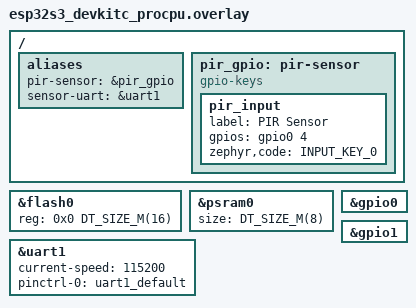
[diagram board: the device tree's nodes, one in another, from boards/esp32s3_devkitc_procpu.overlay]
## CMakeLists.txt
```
# SPDX-License-Identifier: Apache-2.0
# ESP32-S3 Edge AI Gateway - Phase 1 Build Configuration

cmake_minimum_required(VERSION 3.20.0)

find_package(Zephyr REQUIRED HINTS $ENV{ZEPHYR_BASE})

project(esp32s3_edge_ai_gateway)

# 头文件路径
target_include_directories(app PRIVATE include)

# 源文件
target_sources(app PRIVATE
	src/main.c
	src/drivers/pir.c
	src/drivers/uart_driver.c
	src/drivers/lighting.c
	src/logic/presence_state.c
	src/logic/time_period.c
	src/logic/rule_engine.c
	src/logic/fade_control.c
)
```

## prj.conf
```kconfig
# ESP32-S3 Edge AI Gateway Project Configuration
# Phase 1: 基础硬件通信模块

# ================================================================
# GPIO Support
# ================================================================
CONFIG_GPIO=y

# ================================================================
# Serial/UART Support (驱动板通信 + 调试控制台)
# ================================================================
CONFIG_SERIAL=y
CONFIG_UART_INTERRUPT_DRIVEN=y
CONFIG_UART_ASYNC_API=y
CONFIG_UART_ESP32=y

# ================================================================
# PSRAM (N16R8模块 8MB Octal SPI)
# ================================================================
CONFIG_ESP_SPIRAM=y
# CONFIG_ESP_SPIRAM_SIZE is set via DTS in overlay

# ================================================================
# Logging
# ================================================================
CONFIG_LOG=y
CONFIG_LOG_DEFAULT_LEVEL=3
CONFIG_LOG_PRINTK=y

# ================================================================
# Console
# ================================================================
CONFIG_CONSOLE=y
CONFIG_UART_CONSOLE=y

# ================================================================
# 内核配置
# ================================================================
CONFIG_MAIN_THREAD_PRIORITY=10
CONFIG_SYSTEM_WORKQUEUE_STACK_SIZE=2048

# ================================================================
# Networking Support
# ================================================================
CONFIG_NETWORKING=y
CONFIG_NET_NATIVE=y

# ================================================================
# WiFi Support (Phase 2: WF-001)
# ================================================================
CONFIG_WIFI=y
CONFIG_WIFI_ESP32=y
CONFIG_NET_L2_ETHERNET=y
CONFIG_NET_IPV4=y
CONFIG_NET_UDP=y
CONFIG_NET_DHCPV4=y
CONFIG_NET_SOCKETS=y
CONFIG_NET_SOCKETS_POLL_MAX=4

# ================================================================
# Network Buffer Configuration
# ================================================================
CONFIG_NET_PKT_RX_COUNT=16
CONFIG_NET_PKT_TX_COUNT=16
CONFIG_NET_BUF_RX_COUNT=32
CONFIG_NET_BUF_TX_COUNT=32
CONFIG_NET_BUF_DATA_SIZE=128

# ================================================================
# DNS Client (WF-012)
# ================================================================
CONFIG_DNS_RESOLVER=y
CONFIG_DNS_SERVER_IP_ADDRESSES=y

# ================================================================
# SNTP Time Sync (WF-006 ~ WF-010)
# ================================================================
CONFIG_SNTP=y

# ================================================================
# HTTP Client (WF-011 ~ WF-015)
# ================================================================
CONFIG_HTTP_CLIENT=y

# ================================================================
# JSON Parser (WF-022)
# ================================================================
CONFIG_JSON_LIBRARY=y

# ================================================================
# Thread Stack Size (WiFi thread needs more)
# ================================================================
CONFIG_MAIN_STACK_SIZE=4096
CONFIG_SYSTEM_WORKQUEUE_STACK_SIZE=4096
```

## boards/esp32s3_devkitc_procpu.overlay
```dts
/*
 * ESP32-S3 DevKitC Board Overlay (N16R8)
 * Edge AI Gateway Project
 * 
 * Hardware Configuration:
 * - Flash: 16MB (修正N8→N16)
 * - PSRAM: 8MB Octal SPI
 * - GPIO4: PIR传感器输入 (内部上拉)
 * - UART1: 驱动板通信 (TX=GPIO17, RX=GPIO18, 115200bps 8N1)
 */

#include <zephyr/dt-bindings/input/input-event-codes.h>
#include <zephyr/dt-bindings/gpio/gpio.h>

/* ================================================================
 * Flash 修正: N16R8模块使用16MB Flash (默认DTS是8MB)
 * ================================================================ */
&flash0 {
	reg = <0x0 DT_SIZE_M(16)>;  /* 16MB */
};

/* ================================================================
 * PSRAM 启用: 8MB Octal SPI
 * psram0使用'size'属性而非'reg'(其父节点dcache0持有reg)
 * ================================================================ */
&psram0 {
	size = <DT_SIZE_M(8)>;  /* 8MB */
};

/* ================================================================
 * GPIO & 外设别名
 * ================================================================ */
/ {
	aliases {
		pir-sensor = &pir_gpio;
		sensor-uart = &uart1;
	};

	/* PIR传感器 GPIO4: 输入模式, 内部上拉 */
	pir_gpio: pir-sensor {
		compatible = "gpio-keys";
		pir_input: pir_input {
			label = "PIR Sensor";
			gpios = <&gpio0 4 (GPIO_ACTIVE_HIGH | GPIO_PULL_UP)>;
			zephyr,code = <INPUT_KEY_0>;
		};
	};
};

/* ================================================================
 * UART1: 驱动板通信 (GPIO17=TX, GPIO18=RX, 115200bps)
 * pinctrl在板级esp32s3_devkitc-pinctrl.dtsi中已定义
 * ================================================================ */
&uart1 {
	status = "okay";
	current-speed = <115200>;
	pinctrl-0 = <&uart1_default>;
	pinctrl-names = "default";
};

/* ================================================================
 * GPIO控制器启用
 * ================================================================ */
&gpio0 {
	status = "okay";
};

&gpio1 {
	status = "okay";
};
```

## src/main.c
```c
/*
 * ESP32-S3 Edge AI Gateway
 * Main Application Entry Point
 * Phase 3: AI推理系统模块
 *
 * 功能: PIR感应 + UART控制 + WiFi数据 + 环境感知 + AI推理 + 数据记录
 */

#include <zephyr/kernel.h>
#include <zephyr/logging/log.h>

/* Phase 1: 基础硬件通信 */
#include "pir.h"
#include "uart_driver.h"
#include "lighting.h"
#include "presence_state.h"
#include "time_period.h"
#include "rule_engine.h"
#include "fade_control.h"

/* Phase 2: WiFi数据服务 */
#include "wifi_manager.h"
#include "sntp_time_sync.h"
#include "http_client.h"
#include "weather_api.h"
#include "sunrise_sunset.h"
#include "env_dimming.h"

/* Phase 3: AI推理系统 */
#include "ai_infer.h"
#include "data_logger.h"

LOG_MODULE_REGISTER(main, CONFIG_LOG_DEFAULT_LEVEL);

/* ================================================================
 * WiFi状态回调
 * ================================================================ */
static void wifi_state_callback(wifi_state_t state)
{
	switch (state) {
	case WIFI_STATE_GOT_IP:
		LOG_INF("WiFi connected, starting data services...");
		/* 记录事件 */
		data_logger_log_lighting(EVENT_WEATHER_UPDATE, 0, 0, 0);
		break;
	case WIFI_STATE_DISCONNECTED:
		LOG_WRN("WiFi disconnected, using offline mode");
		break;
	default:
		break;
	}
}

/* ================================================================
 * 初始化流程
 * ================================================================ */
int main(void)
{
	int ret;

	LOG_INF("========================================");
	LOG_INF("ESP32-S3 Edge AI Gateway Starting...");
	LOG_INF("Phase 3: AI Inference System");
	LOG_INF("========================================");

	/* ============================================================
	 * Phase 1: 基础硬件初始化
	 * ============================================================ */

	ret = pir_init();
	if (ret < 0) { LOG_ERR("PIR init failed"); return ret; }

	ret = uart_driver_init();
	if (ret < 0) { LOG_ERR("UART init failed"); return ret; }

	ret = lighting_init();
	if (ret < 0) { LOG_ERR("Lighting init failed"); }

	ret = presence_state_init();
	if (ret < 0) { LOG_ERR("Presence FSM init failed"); }

	ret = rule_engine_init();
	if (ret < 0) { LOG_ERR("Rule engine init failed"); }

	ret = fade_control_init();
	if (ret < 0) { LOG_ERR("Fade control init failed"); }

	LOG_INF("Phase 1 complete!");

	/* ============================================================
	 * Phase 2: WiFi数据服务初始化
	 * ============================================================ */

	ret = wifi_manager_init();
	if (ret < 0) { LOG_ERR("WiFi manager init failed"); }
	wifi_manager_register_state_cb(wifi_state_callback);
	if (ret == 0) {
		wifi_manager_start();
	}

	ret = sntp_time_init();
	if (ret < 0) { LOG_ERR("SNTP init failed"); }
	if (ret == 0) {
		sntp_time_start();
	}

	ret = http_client_init();
	if (ret < 0) { LOG_ERR("HTTP client init failed"); }

	ret = weather_api_init();
	if (ret < 0) { LOG_ERR("Weather API init failed"); }
	if (ret == 0) {
		weather_api_start();
	}

	ret = sun_api_init();
	if (ret < 0) { LOG_ERR("Sunrise-sunset API init failed"); }
	if (ret == 0) {
		sun_api_start();
	}

	ret = env_dimming_init();
	if (ret < 0) { LOG_ERR("Environment dimming init failed"); }

	LOG_INF("Phase 2 complete!");

	/* ============================================================
	 * Phase 3: AI推理系统初始化
	 * ============================================================ */

	/* AI-021 ~ AI-022: 数据记录器初始化 */
	ret = data_logger_init();
	if (ret < 0) {
		LOG_ERR("Data logger init failed");
	}

	/* AI-008 ~ AI-010: AI推理引擎初始化 */
	ret = ai_infer_init();
	if (ret != AI_STATUS_OK) {
		LOG_WRN("AI inference init failed (err %d) - falling back to rules", ret);
		/* 继续运行, 使用规则引擎作为后备 */
	} else {
		LOG_INF("AI inference engine loaded!");

		/* AI-020: 启动AI推理线程 */
		ai_infer_thread_start();
	}

	LOG_INF("Phase 3 complete!");
	LOG_INF("System ready - entering main control loop");

	/* ================================================================
	 * 主控制循环
	 * ================================================================
	 * 周期: 每1秒执行一次
	 * 功能:
	 *   1. 更新人员状态机
	 *   2. 检查WiFi连接状态
	 *   3. AI推理或规则引擎计算
	 *   4. 渐变控制
	 *   5. 事件记录
	 */
	lighting_settings_t settings;
	lighting_settings_t prev_settings = {0, 0};
	env_dimming_result_t env_result;

	while (1) {
		/* 更新人员状态机 */
		presence_state_t presence = presence_state_update();

		/* 获取当前时段 */
		time_period_t period = time_period_get_current();

		/* 优先使用AI推理, 否则使用规则引擎 */
		if (ai_infer_is_ready()) {
			/* AI推理已在独立线程中运行, 这里只检查状态 */
			uint16_t cur_temp;
			uint8_t cur_bright;
			fade_get_current(&cur_temp, &cur_bright);

			settings.color_temp = cur_temp;
			settings.brightness = cur_bright;
		} else {
			/* 后备: 使用环境感知调光 (Phase 2) */
			ret = env_dimming_calculate(presence, period, &env_result);
			if (ret == 0) {
				settings = env_result.final_;
			} else {
				/* 最终后备: 基础规则引擎 */
				rule_calculate_settings(presence, period, &settings);
			}

			/* 执行渐变控制 */
			if (settings.color_temp != prev_settings.color_temp ||
			    settings.brightness != prev_settings.brightness) {

				LOG_INF("Rule: %s/%s → %dK @ %d%%",
					presence == PRESENCE_TIMEOUT ? "OFF" : "ON",
					time_period_name(period),
					settings.color_temp, settings.brightness);

				if (settings.brightness == 0) {
					fade_to_target(settings.color_temp, 0, 1000);
				} else {
					fade_to_target(settings.color_temp, settings.brightness, 2000);
				}

				/* 记录事件 */
				data_logger_log_lighting(
					settings.brightness == 0 ? EVENT_LIGHTS_OFF : EVENT_LIGHTS_ON,
					settings.color_temp, settings.brightness, 0);

				prev_settings = settings;
			}
		}

		/* WiFi离线处理 */
		if (!wifi_manager_is_connected()) {
			static bool offline_logged = false;
			if (!offline_logged) {
				LOG_WRN("WiFi offline - using defaults");
				offline_logged = true;
			}
		}

		/* 调试日志 */
		if (presence == PRESENCE_YES) {
			LOG_DBG("PRESENT | %s | %dK @ %d%%",
				time_period_name(period),
				settings.color_temp, settings.brightness);
		} else if (presence == PRESENCE_NO) {
			uint32_t sec = presence_get_absence_seconds();
			LOG_DBG("ABSENT %ds | %s", sec, time_period_name(period));
		}

		k_sleep(K_SECONDS(1));
	}

	return 0;
}
```

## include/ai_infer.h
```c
/*
 * AI Inference Engine - TFLM推理封装
 * Phase 3: AI-008 ~ AI-012, AI-017 ~ AI-020
 *
 * 功能: 模型加载、特征填充、推理执行、后处理
 */

#ifndef AI_INFER_H
#define AI_INFER_H

#include <stdint.h>
#include <stdbool.h>

/* ================================================================
 * AI-013: 特征结构定义
 * ================================================================ */
#define AI_FEATURE_COUNT  7

typedef struct {
	float hour_sin;           /* [-1, 1] 时间正弦编码 */
	float hour_cos;           /* [-1, 1] 时间余弦编码 */
	float sunset_proximity;   /* [-1, 1] 日落临近度 */
	float sunrise_hour_norm;  /* [0, 1] 日出时间归一化 */
	float sunset_hour_norm;   /* [0, 1] 日落时间归一化 */
	float weather;            /* [0, 1] 天气编码 */
	float presence;           /* {0, 1} 人员存在 */
} ai_features_t;

/* 输出结构 */
typedef struct {
	uint16_t color_temp;      /* 2700-6500 K */
	uint8_t brightness;       /* 0-100 % */
} ai_output_t;

/* 推理状态 */
typedef enum {
	AI_STATUS_OK = 0,
	AI_STATUS_ERROR_INIT = -1,
	AI_STATUS_ERROR_MODEL = -2,
	AI_STATUS_ERROR_TENSOR = -3,
	AI_STATUS_ERROR_INVOKE = -4,
	AI_STATUS_ERROR_INPUT = -5,
} ai_status_t;

/* ================================================================
 * AI-008 ~ AI-012: 初始化与推理
 * ================================================================ */

/**
 * @brief 初始化AI推理引擎 (AI-008 ~ AI-010)
 * @return AI_STATUS_OK=成功
 */
ai_status_t ai_infer_init(void);

/**
 * @brief 检查AI引擎是否就绪
 * @return true=已初始化
 */
bool ai_infer_is_ready(void);

/**
 * @brief 执行推理 (AI-017)
 * @param features 输入特征
 * @param output   输出结果
 * @return AI_STATUS_OK=成功
 */
ai_status_t ai_infer_run(const ai_features_t *features, ai_output_t *output);

/**
 * @brief 获取推理延迟 (AI-028)
 * @return 上次推理耗时(微秒)
 */
uint32_t ai_infer_get_latency_us(void);

/* ================================================================
 * AI-014 ~ AI-016: 特征工程
 * ================================================================ */

/**
 * @brief 计算时间特征 (AI-014)
 * @param hour 当前小时 (0-23)
 * @param features 输出特征结构
 */
void ai_calc_time_features(float hour, ai_features_t *features);

/**
 * @brief 计算日落临近度 (AI-015)
 * @param hour 当前小时
 * @param sunset_hour 日落时间(小时)
 * @return 临近度值 [-1, 1]
 */
float ai_calc_sunset_proximity(float hour, float sunset_hour);

/**
 * @brief 组装完整特征向量 (AI-016)
 * @param hour 当前小时
 * @param weather 天气编码 (0-1)
 * @param presence 人员存在 (0/1)
 * @param sunrise_hour 日出时间
 * @param sunset_hour 日落时间
 * @param features 输出特征结构
 */
void ai_assemble_features(float hour, float weather, float presence,
			  float sunrise_hour, float sunset_hour,
			  ai_features_t *features);

/* ================================================================
 * AI-018: 后处理
 * ================================================================ */

/**
 * @brief 推理结果后处理
 * - 无人强制关灯
 * - 深夜限制亮度
 * - 范围限制
 * @param raw_output 原始推理输出
 * @param presence   人员状态
 * @param hour       当前小时
 * @param final_output 最终输出
 */
void ai_post_process(const ai_output_t *raw_output, float presence,
		     float hour, ai_output_t *final_output);

/* ================================================================
 * AI-020: 推理线程
 * ================================================================ */

/**
 * @brief 启动AI推理线程
 */
void ai_infer_thread_start(void);

/**
 * @brief 停止AI推理线程
 */
void ai_infer_thread_stop(void);

/* 推理周期 */
#define AI_INFERENCE_INTERVAL_MS  30000  /* 30秒 */

/* ================================================================
 * P0: 非对称 Debounce 状态机参数
 * ================================================================ */

/* 上升沿延迟：0ms（开灯要快） */
#define PRESENCE_RISE_DELAY_MS      0

/* 下降沿延迟：5分钟（关灯要慢，用户可能只是静坐） */
#define PRESENCE_FALL_DELAY_MS      300000

/**
 * @brief 更新稳定 presence 状态
 * @param raw_presence 原始 PIR 状态 (0/1)
 * @param now_ms 当前时间戳 (毫秒)
 * @return 稳定的 presence 状态
 */
float ai_update_stable_presence(bool raw_presence, int64_t now_ms);

/**
 * @brief 获取当前稳定 presence 状态
 * @return 稳定状态 (0.0 或 1.0)
 */
float ai_get_stable_presence(void);

/**
 * @brief 重置 presence 状态机
 */
void ai_presence_reset(void);

#endif /* AI_INFER_H */
```

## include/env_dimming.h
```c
/*
 * Environment-Aware Dimming - 环境感知调光算法
 * Phase 2: WF-026 ~ WF-030
 *
 * 功能: 日落临近度计算、天气补偿、日落渐变、增强调光引擎
 */

#ifndef ENV_DIMMING_H
#define ENV_DIMMING_H

#include <stdint.h>
#include <stdbool.h>
#include "rule_engine.h"
#include "weather_api.h"
#include "sunrise_sunset.h"

/* 补偿参数 */
#define WEATHER_COMP_MAX       25    /* 天气补偿最大增加 25% */
#define SUNSET_PROX_MAX        15    /* 日落临近最大增加 15% */
#define SUNSET_PROX_RANGE_HR   2.0f  /* 日落临近范围: 前后2小时 */

/* 增强调光参数结构体 */
typedef struct {
	lighting_settings_t base;      /* 基础参数 (时段规则) */
	float weather_comp;           /* 天气补偿量 (%) */
	float sunset_comp;            /* 日落补偿量 (%) */
	lighting_settings_t final_;    /* 最终参数 */
} env_dimming_result_t;

/**
 * @brief 初始化环境感知调光模块 (WF-029)
 * @return 0=成功
 */
int env_dimming_init(void);

/**
 * @brief 计算日落临近度 (WF-026)
 * @return 0.0 ~ 1.0 (日落时刻为1.0)
 */
float env_calc_sunset_proximity(void);

/**
 * @brief 计算天气补偿量 (WF-027)
 * @param weather_code 天气编码 (0.0 ~ 1.0)
 * @return 补偿量 (%), 阴天增加最多
 */
float env_calc_weather_compensation(float weather_code);

/**
 * @brief 计算日落渐变补偿量 (WF-028)
 * @param proximity 日落临近度
 * @return 补偿量 (%)
 */
float env_calc_sunset_compensation(float proximity);

/**
 * @brief 增强调光引擎: 融合天气+日落补偿 (WF-029)
 * @param presence 人员状态
 * @param period   时段
 * @param result   输出结果
 * @return 0=成功
 */
int env_dimming_calculate(int presence, int period, env_dimming_result_t *result);

/**
 * @brief 获取增强后的照明参数 (便捷函数)
 * @param settings 输出照明参数
 * @return 0=成功
 */
int env_get_enhanced_settings(lighting_settings_t *settings);

/**
 * @brief 联调测试 (WF-030)
 * 打印各种场景下的调光参数
 */
void env_dimming_test(void);

#endif /* ENV_DIMMING_H */
```

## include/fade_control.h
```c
/*
 * Fade Control Module - 渐变控制
 * Phase 1: HW-020
 */

#ifndef FADE_CONTROL_H
#define FADE_CONTROL_H

#include <stdint.h>
#include <stdbool.h>
#include "lighting.h"

/* 默认渐变时间 */
#define FADE_DEFAULT_DURATION_MS  1000  /* 1秒 */
#define FADE_STEP_INTERVAL_MS     50    /* 每50ms更新一次 */

/**
 * @brief 初始化渐变控制模块
 * @return 0=成功
 */
int fade_control_init(void);

/**
 * @brief 平滑渐变到目标色温和光强
 * @param target_temp   目标色温 (2700-6500)
 * @param target_bright 目标光强 (0-100)
 * @param duration_ms   渐变时间 (毫秒)
 * @return 0=成功, 负值=失败
 */
int fade_to_target(uint16_t target_temp, uint8_t target_bright,
		   uint32_t duration_ms);

/**
 * @brief 立即设置 (无渐变)
 * @param temp   色温
 * @param bright 光强
 * @return 0=成功
 */
int fade_set_immediate(uint16_t temp, uint8_t bright);

/**
 * @brief 检查是否正在渐变中
 * @return true=正在渐变
 */
bool fade_is_in_progress(void);

/**
 * @brief 获取当前设置值
 * @param temp   输出当前色温
 * @param bright 输出当前光强
 */
void fade_get_current(uint16_t *temp, uint8_t *bright);

#endif /* FADE_CONTROL_H */
```

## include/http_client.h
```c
/*
 * HTTP Client - HTTP请求模块
 * Phase 2: WF-011 ~ WF-015
 *
 * 功能: HTTP GET请求、DNS解析、响应缓冲、超时处理
 */

#ifndef HTTP_CLIENT_H
#define HTTP_CLIENT_H

#include <stdint.h>
#include <stddef.h>

/* HTTP响应缓冲区大小 */
#define HTTP_RESPONSE_BUF_SIZE  4096

/* HTTP超时 */
#define HTTP_REQUEST_TIMEOUT_S  5

/* HTTP状态码 */
#define HTTP_STATUS_OK          200

/* HTTP响应结构体 */
typedef struct {
	int status_code;                   /* HTTP状态码 */
	char *body;                        /* 响应体 (动态分配或外部缓冲区) */
	size_t body_len;                   /* 响应体长度 */
	size_t buf_size;                   /* 缓冲区总大小 */
} http_response_t;

/**
 * @brief 初始化HTTP客户端 (WF-011)
 * @return 0=成功, 负值=失败
 */
int http_client_init(void);

/**
 * @brief 执行HTTP GET请求 (WF-013)
 * @param host     主机名 (如 "wttr.in")
 * @param path     路径 (如 "/Beijing?format=3")
 * @param port     端口 ("80" 或 "443")
 * @param response 输出响应结构体 (调用者分配body缓冲区)
 * @return 0=成功, 负值=失败
 */
int http_get(const char *host, const char *path, const char *port,
	     http_response_t *response);

/**
 * @brief 初始化HTTP响应结构体 (WF-014)
 * @param response 响应结构体
 * @param buf      外部提供的缓冲区 (至少HTTP_RESPONSE_BUF_SIZE)
 * @param buf_size 缓冲区大小
 */
void http_response_init(http_response_t *response, char *buf, size_t buf_size);

/**
 * @brief 清理HTTP响应
 * @param response 响应结构体
 */
void http_response_cleanup(http_response_t *response);

#endif /* HTTP_CLIENT_H */
```

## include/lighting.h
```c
/*
 * Lighting Command Interface - 驱动板调光控制
 * Phase 1: HW-013
 */

#ifndef LIGHTING_H
#define LIGHTING_H

#include <stdint.h>

/* 命令码定义 (驱动板协议) */
#define CMD_SET_COLOR_TEMP   0x01  /* 设置色温 (小端16位) */
#define CMD_SET_BRIGHTNESS   0x02  /* 设置光强 (1字节百分比) */
#define CMD_SET_BOTH         0x03  /* 同时设置色温+光强 */
#define CMD_GET_STATUS       0x04  /* 查询驱动板状态 */

/* 响应状态码 */
#define RESP_ACK             0x00  /* 成功确认 */
#define RESP_NAK             0xFF  /* 失败/拒绝 */

/* 参数范围 */
#define COLOR_TEMP_MIN       2700
#define COLOR_TEMP_MAX       6500
#define BRIGHTNESS_MIN       0
#define BRIGHTNESS_MAX       100

/**
 * @brief 初始化照明控制模块
 * @return 0=成功, 负值=失败
 */
int lighting_init(void);

/**
 * @brief 设置灯具色温
 * @param color_temp 色温值 (2700-6500K)
 * @return 0=成功, 负值=失败
 */
int lighting_set_color_temp(uint16_t color_temp);

/**
 * @brief 设置灯具光强
 * @param brightness 光强百分比 (0-100)
 * @return 0=成功, 负值=失败
 */
int lighting_set_brightness(uint8_t brightness);

/**
 * @brief 同时设置色温和光强
 * @param color_temp 色温值 (2700-6500K)
 * @param brightness 光强百分比 (0-100)
 * @return 0=成功, 负值=失败
 */
int lighting_set_both(uint16_t color_temp, uint8_t brightness);

/**
 * @brief 查询驱动板当前状态
 * @return 0=成功, 负值=失败
 */
int lighting_get_status(void);

#endif /* LIGHTING_H */
```

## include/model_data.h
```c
/*
 * Lighting MLP Model Data - INT8 Quantized
 * Auto-generated by train_model.py
 * DO NOT EDIT
 */

#ifndef LIGHTING_MODEL_DATA_H_
#define LIGHTING_MODEL_DATA_H_

#include <stdint.h>

const unsigned int g_lighting_model_data_len = 2648;
const alignas(16) unsigned char g_lighting_model_data[] = {
    0x20, 0x00, 0x00, 0x00, 0x54, 0x46, 0x4c, 0x33, 0x00, 0x00, 0x00, 0x00,
    0x14, 0x00, 0x20, 0x00, 0x1c, 0x00, 0x18, 0x00, 0x14, 0x00, 0x10, 0x00,
    0x0c, 0x00, 0x00, 0x00, 0x08, 0x00, 0x04, 0x00, 0x14, 0x00, 0x00, 0x00,
    0x1c, 0x00, 0x00, 0x00, 0x8c, 0x00, 0x00, 0x00, 0xe4, 0x00, 0x00, 0x00,
    0xbc, 0x02, 0x00, 0x00, 0xcc, 0x02, 0x00, 0x00, 0xe8, 0x09, 0x00, 0x00,
    0x03, 0x00, 0x00, 0x00, 0x01, 0x00, 0x00, 0x00, 0x04, 0x00, 0x00, 0x00,
    0xfa, 0xfc, 0xff, 0xff, 0x0c, 0x00, 0x00, 0x00, 0x1c, 0x00, 0x00, 0x00,
    0x3c, 0x00, 0x00, 0x00, 0x0f, 0x00, 0x00, 0x00, 0x73, 0x65, 0x72, 0x76,
    0x69, 0x6e, 0x67, 0x5f, 0x64, 0x65, 0x66, 0x61, 0x75, 0x6c, 0x74, 0x00,
    0x01, 0x00, 0x00, 0x00, 0x04, 0x00, 0x00, 0x00, 0x90, 0xff, 0xff, 0xff,
    0x07, 0x00, 0x00, 0x00, 0x04, 0x00, 0x00, 0x00, 0x08, 0x00, 0x00, 0x00,
    0x6f, 0x75, 0x74, 0x70, 0x75, 0x74, 0x5f, 0x30, 0x00, 0x00, 0x00, 0x00,
    0x01, 0x00, 0x00, 0x00, 0x04, 0x00, 0x00, 0x00, 0xce, 0xfd, 0xff, 0xff,
    0x04, 0x00, 0x00, 0x00, 0x0c, 0x00, 0x00, 0x00, 0x6b, 0x65, 0x72, 0x61,
    0x73, 0x5f, 0x74, 0x65, 0x6e, 0x73, 0x6f, 0x72, 0x00, 0x00, 0x00, 0x00,
    0x02, 0x00, 0x00, 0x00, 0x34, 0x00, 0x00, 0x00, 0x04, 0x00, 0x00, 0x00,
    0xdc, 0xff, 0xff, 0xff, 0x0a, 0x00, 0x00, 0x00, 0x04, 0x00, 0x00, 0x00,
    0x13, 0x00, 0x00, 0x00, 0x43, 0x4f, 0x4e, 0x56, 0x45, 0x52, 0x53, 0x49,
    0x4f, 0x4e, 0x5f, 0x4d, 0x45, 0x54, 0x41, 0x44, 0x41, 0x54, 0x41, 0x00,
    0x08, 0x00, 0x0c, 0x00, 0x08, 0x00, 0x04, 0x00, 0x08, 0x00, 0x00, 0x00,
    0x09, 0x00, 0x00, 0x00, 0x04, 0x00, 0x00, 0x00, 0x13, 0x00, 0x00, 0x00,
    0x6d, 0x69, 0x6e, 0x5f, 0x72, 0x75, 0x6e, 0x74, 0x69, 0x6d, 0x65, 0x5f,
    0x76, 0x65, 0x72, 0x73, 0x69, 0x6f, 0x6e, 0x00, 0x0b, 0x00, 0x00, 0x00,
    0xd4, 0x01, 0x00, 0x00, 0xcc, 0x01, 0x00, 0x00, 0xb4, 0x01, 0x00, 0x00,
    0x7c, 0x01, 0x00, 0x00, 0x2c, 0x01, 0x00, 0x00, 0xac, 0x00, 0x00, 0x00,
    0xa4, 0x00, 0x00, 0x00, 0x9c, 0x00, 0x00, 0x00, 0x94, 0x00, 0x00, 0x00,
    0x74, 0x00, 0x00, 0x00, 0x04, 0x00, 0x00, 0x00, 0x76, 0xfe, 0xff, 0xff,
    0x04, 0x00, 0x00, 0x00, 0x60, 0x00, 0x00, 0x00, 0x0c, 0x00, 0x00, 0x00,
    0x08, 0x00, 0x0e, 0x00, 0x08, 0x00, 0x04, 0x00, 0x08, 0x00, 0x00, 0x00,
    0x10, 0x00, 0x00, 0x00, 0x28, 0x00, 0x00, 0x00, 0x00, 0x00, 0x06, 0x00,
    0x08, 0x00, 0x04, 0x00, 0x06, 0x00, 0x00, 0x00, 0x04, 0x00, 0x00, 0x00,
    0x01, 0x00, 0x00, 0x00, 0xeb, 0x03, 0x00, 0x00, 0x0c, 0x00, 0x18, 0x00,
    0x14, 0x00, 0x10, 0x00, 0x0c, 0x00, 0x04, 0x00, 0x0c, 0x00, 0x00, 0x00,
    0x8a, 0x86, 0xd6, 0x43, 0x1b, 0x89, 0x45, 0x2d, 0x02, 0x00, 0x00, 0x00,
    0x02, 0x00, 0x00, 0x00, 0x04, 0x00, 0x00, 0x00, 0x06, 0x00, 0x00, 0x00,
    0x32, 0x2e, 0x32, 0x31, 0x2e, 0x30, 0x00, 0x00, 0xe2, 0xfe, 0xff, 0xff,
    0x04, 0x00, 0x00, 0x00, 0x10, 0x00, 0x00, 0x00, 0x31, 0x2e, 0x31, 0x34,
    0x2e, 0x30, 0x00, 0x00, 0x00, 0x00, 0x00, 0x00, 0x00, 0x00, 0x00, 0x00,
    0x2c, 0xfe, 0xff, 0xff, 0x30, 0xfe, 0xff, 0xff, 0x34, 0xfe, 0xff, 0xff,
    0x0a, 0xff, 0xff, 0xff, 0x04, 0x00, 0x00, 0x00, 0x70, 0x00, 0x00, 0x00,
    0xce, 0xc9, 0x1a, 0x24, 0x24, 0xfa, 0x81, 0x33, 0x7f, 0x3d, 0x59, 0x3c,
    0x06, 0xd0, 0xef, 0xe5, 0x1f, 0x0b, 0xfc, 0x2f, 0x7f, 0x81, 0xdb, 0x40,
    0xee, 0xb6, 0xc3, 0xe7, 0x1d, 0x50, 0x7f, 0x36, 0x16, 0x00, 0xc8, 0xed,
    0x8d, 0xc5, 0xaf, 0x81, 0xfb, 0xb5, 0xe5, 0xc3, 0x60, 0x04, 0xde, 0x20,
    0x7f, 0xfc, 0x9f, 0x81, 0xfe, 0x03, 0xf7, 0xcf, 0x7f, 0x13, 0xcf, 0x0c,
    0x26, 0xef, 0x20, 0x03, 0x00, 0x05, 0x39, 0x2c, 0x06, 0x81, 0x81, 0xd5,
    0x57, 0xc4, 0xca, 0x1a, 0x0c, 0xde, 0x66, 0x81, 0x8a, 0xb8, 0xc0, 0xc6,
    0x15, 0x44, 0x7f, 0xdb, 0xe0, 0x11, 0xf6, 0x29, 0x7a, 0x69, 0xf5, 0x3a,
    0x7f, 0x32, 0x2f, 0xe6, 0x2e, 0x00, 0x4d, 0xce, 0x81, 0xc6, 0x1b, 0xa8,
    0xf5, 0x7f, 0xcb, 0x1a, 0x86, 0xff, 0xff, 0xff, 0x04, 0x00, 0x00, 0x00,
    0x40, 0x00, 0x00, 0x00, 0x48, 0x17, 0x00, 0x00, 0x09, 0x2f, 0x00, 0x00,
    0x54, 0xfc, 0xff, 0xff, 0xd8, 0x08, 0x00, 0x00, 0x2c, 0x32, 0x00, 0x00,
    0x43, 0xfd, 0xff, 0xff, 0xdd, 0x01, 0x00, 0x00, 0xd3, 0x1e, 0x00, 0x00,
    0x11, 0xf6, 0xff, 0xff, 0x02, 0x21, 0x00, 0x00, 0xf3, 0x03, 0x00, 0x00,
    0x0d, 0xf3, 0xff, 0xff, 0x8b, 0xf3, 0xff, 0xff, 0xf3, 0x0c, 0x00, 0x00,
    0xbd, 0x22, 0x00, 0x00, 0x77, 0x0a, 0x00, 0x00, 0xd2, 0xff, 0xff, 0xff,
    0x04, 0x00, 0x00, 0x00, 0x20, 0x00, 0x00, 0x00, 0xb7, 0xdb, 0x24, 0xec,
    0xc5, 0x05, 0x1c, 0xbc, 0x3a, 0x81, 0xd5, 0x0b, 0x50, 0xdf, 0xe0, 0x22,
    0x9d, 0xe7, 0x2a, 0xaf, 0xed, 0x14, 0x4d, 0xd7, 0x31, 0x81, 0x23, 0x05,
    0x10, 0x07, 0xa2, 0xe4, 0x00, 0x00, 0x06, 0x00, 0x08, 0x00, 0x04, 0x00,
    0x06, 0x00, 0x00, 0x00, 0x04, 0x00, 0x00, 0x00, 0x08, 0x00, 0x00, 0x00,
    0x15, 0xfb, 0xff, 0xff, 0xed, 0xf7, 0xff, 0xff, 0x48, 0xff, 0xff, 0xff,
    0x4c, 0xff, 0xff, 0xff, 0x0f, 0x00, 0x00, 0x00, 0x4d, 0x4c, 0x49, 0x52,
    0x20, 0x43, 0x6f, 0x6e, 0x76, 0x65, 0x72, 0x74, 0x65, 0x64, 0x2e, 0x00,
    0x01, 0x00, 0x00, 0x00, 0x14, 0x00, 0x00, 0x00, 0x00, 0x00, 0x0e, 0x00,
    0x18, 0x00, 0x14, 0x00, 0x10, 0x00, 0x0c, 0x00, 0x08, 0x00, 0x04, 0x00,
    0x0e, 0x00, 0x00, 0x00, 0x14, 0x00, 0x00, 0x00, 0x1c, 0x00, 0x00, 0x00,
    0xe4, 0x00, 0x00, 0x00, 0xe8, 0x00, 0x00, 0x00, 0xec, 0x00, 0x00, 0x00,
    0x04, 0x00, 0x00, 0x00, 0x6d, 0x61, 0x69, 0x6e, 0x00, 0x00, 0x00, 0x00,
    0x03, 0x00, 0x00, 0x00, 0x8c, 0x00, 0x00, 0x00, 0x44, 0x00, 0x00, 0x00,
    0x10, 0x00, 0x00, 0x00, 0x00, 0x00, 0x0a, 0x00, 0x10, 0x00, 0x0c, 0x00,
    0x08, 0x00, 0x04, 0x00, 0x0a, 0x00, 0x00, 0x00, 0x0c, 0x00, 0x00, 0x00,
    0x10, 0x00, 0x00, 0x00, 0x01, 0x00, 0x00, 0x00, 0x01, 0x00, 0x00, 0x00,
    0x07, 0x00, 0x00, 0x00, 0x01, 0x00, 0x00, 0x00, 0x06, 0x00, 0x00, 0x00,
    0x00, 0x00, 0x0e, 0x00, 0x14, 0x00, 0x00, 0x00, 0x10, 0x00, 0x0c, 0x00,
    0x0b, 0x00, 0x04, 0x00, 0x0e, 0x00, 0x00, 0x00, 0x14, 0x00, 0x00, 0x00,
    0x00, 0x00, 0x00, 0x08, 0x10, 0x00, 0x00, 0x00, 0x14, 0x00, 0x00, 0x00,
    0x04, 0x00, 0x04, 0x00, 0x04, 0x00, 0x00, 0x00, 0x01, 0x00, 0x00, 0x00,
    0x06, 0x00, 0x00, 0x00, 0x03, 0x00, 0x00, 0x00, 0x05, 0x00, 0x00, 0x00,
    0x02, 0x00, 0x00, 0x00, 0x01, 0x00, 0x00, 0x00, 0x00, 0x00, 0x0e, 0x00,
    0x16, 0x00, 0x00, 0x00, 0x10, 0x00, 0x0c, 0x00, 0x0b, 0x00, 0x04, 0x00,
    0x0e, 0x00, 0x00, 0x00, 0x18, 0x00, 0x00, 0x00, 0x00, 0x00, 0x00, 0x08,
    0x18, 0x00, 0x00, 0x00, 0x1c, 0x00, 0x00, 0x00, 0x00, 0x00, 0x06, 0x00,
    0x08, 0x00, 0x07, 0x00, 0x06, 0x00, 0x00, 0x00, 0x00, 0x00, 0x00, 0x01,
    0x01, 0x00, 0x00, 0x00, 0x05, 0x00, 0x00, 0x00, 0x03, 0x00, 0x00, 0x00,
    0x00, 0x00, 0x00, 0x00, 0x04, 0x00, 0x00, 0x00, 0x03, 0x00, 0x00, 0x00,
    0x01, 0x00, 0x00, 0x00, 0x07, 0x00, 0x00, 0x00, 0x01, 0x00, 0x00, 0x00,
    0x00, 0x00, 0x00, 0x00, 0x08, 0x00, 0x00, 0x00, 0x7c, 0x05, 0x00, 0x00,
    0xec, 0x04, 0x00, 0x00, 0x58, 0x04, 0x00, 0x00, 0x14, 0x03, 0x00, 0x00,
    0xe8, 0x01, 0x00, 0x00, 0x24, 0x01, 0x00, 0x00, 0x80, 0x00, 0x00, 0x00,
    0x04, 0x00, 0x00, 0x00, 0xba, 0xfa, 0xff, 0xff, 0x00, 0x00, 0x00, 0x01,
    0x18, 0x00, 0x00, 0x00, 0x20, 0x00, 0x00, 0x00, 0x3c, 0x00, 0x00, 0x00,
    0x08, 0x00, 0x00, 0x00, 0x00, 0x00, 0x00, 0x09, 0x50, 0x00, 0x00, 0x00,
    0x02, 0x00, 0x00, 0x00, 0xff, 0xff, 0xff, 0xff, 0x02, 0x00, 0x00, 0x00,
    0xa4, 0xfa, 0xff, 0xff, 0x08, 0x00, 0x00, 0x00, 0x10, 0x00, 0x00, 0x00,
    0x01, 0x00, 0x00, 0x00, 0x80, 0xff, 0xff, 0xff, 0xff, 0xff, 0xff, 0xff,
    0x01, 0x00, 0x00, 0x00, 0x00, 0x00, 0x80, 0x3b, 0x1b, 0x00, 0x00, 0x00,
    0x53, 0x74, 0x61, 0x74, 0x65, 0x66, 0x75, 0x6c, 0x50, 0x61, 0x72, 0x74,
    0x69, 0x74, 0x69, 0x6f, 0x6e, 0x65, 0x64, 0x43, 0x61, 0x6c, 0x6c, 0x5f,
    0x31, 0x3a, 0x30, 0x00, 0x02, 0x00, 0x00, 0x00, 0x01, 0x00, 0x00, 0x00,
    0x02, 0x00, 0x00, 0x00, 0x32, 0xfb, 0xff, 0xff, 0x00, 0x00, 0x00, 0x01,
    0x18, 0x00, 0x00, 0x00, 0x20, 0x00, 0x00, 0x00, 0x40, 0x00, 0x00, 0x00,
    0x07, 0x00, 0x00, 0x00, 0x00, 0x00, 0x00, 0x09, 0x78, 0x00, 0x00, 0x00,
    0x02, 0x00, 0x00, 0x00, 0xff, 0xff, 0xff, 0xff, 0x02, 0x00, 0x00, 0x00,
    0x1c, 0xfb, 0xff, 0xff, 0x08, 0x00, 0x00, 0x00, 0x14, 0x00, 0x00, 0x00,
    0x01, 0x00, 0x00, 0x00, 0x4b, 0x00, 0x00, 0x00, 0x00, 0x00, 0x00, 0x00,
    0x00, 0x00, 0x00, 0x00, 0x01, 0x00, 0x00, 0x00, 0x58, 0xca, 0x33, 0x3d,
    0x3e, 0x00, 0x00, 0x00, 0x6c, 0x69, 0x67, 0x68, 0x74, 0x69, 0x6e, 0x67,
    0x5f, 0x6d, 0x6c, 0x70, 0x5f, 0x31, 0x2f, 0x6f, 0x75, 0x74, 0x70, 0x75,
    0x74, 0x5f, 0x31, 0x2f, 0x4d, 0x61, 0x74, 0x4d, 0x75, 0x6c, 0x3b, 0x6c,
    0x69, 0x67, 0x68, 0x74, 0x69, 0x6e, 0x67, 0x5f, 0x6d, 0x6c, 0x70, 0x5f,
    0x31, 0x2f, 0x6f, 0x75, 0x74, 0x70, 0x75, 0x74, 0x5f, 0x31, 0x2f, 0x42,
    0x69, 0x61, 0x73, 0x41, 0x64, 0x64, 0x00, 0x00, 0x02, 0x00, 0x00, 0x00,
    0x01, 0x00, 0x00, 0x00, 0x02, 0x00, 0x00, 0x00, 0xd2, 0xfb, 0xff, 0xff,
    0x00, 0x00, 0x00, 0x01, 0x18, 0x00, 0x00, 0x00, 0x20, 0x00, 0x00, 0x00,
    0x3c, 0x00, 0x00, 0x00, 0x06, 0x00, 0x00, 0x00, 0x00, 0x00, 0x00, 0x09,
    0x98, 0x00, 0x00, 0x00, 0x02, 0x00, 0x00, 0x00, 0xff, 0xff, 0xff, 0xff,
    0x10, 0x00, 0x00, 0x00, 0xbc, 0xfb, 0xff, 0xff, 0x08, 0x00, 0x00, 0x00,
    0x10, 0x00, 0x00, 0x00, 0x01, 0x00, 0x00, 0x00, 0x80, 0xff, 0xff, 0xff,
    0xff, 0xff, 0xff, 0xff, 0x01, 0x00, 0x00, 0x00, 0x79, 0x02, 0x08, 0x3c,
    0x61, 0x00, 0x00, 0x00, 0x6c, 0x69, 0x67, 0x68, 0x74, 0x69, 0x6e, 0x67,
    0x5f, 0x6d, 0x6c, 0x70, 0x5f, 0x31, 0x2f, 0x68, 0x69, 0x64, 0x64, 0x65,
    0x6e, 0x5f, 0x31, 0x5f, 0x31, 0x2f, 0x4d, 0x61, 0x74, 0x4d, 0x75, 0x6c,
    0x3b, 0x6c, 0x69, 0x67, 0x68, 0x74, 0x69, 0x6e, 0x67, 0x5f, 0x6d, 0x6c,
    0x70, 0x5f, 0x31, 0x2f, 0x68, 0x69, 0x64, 0x64, 0x65, 0x6e, 0x5f, 0x31,
    0x5f, 0x31, 0x2f, 0x52, 0x65, 0x6c, 0x75, 0x3b, 0x6c, 0x69, 0x67, 0x68,
    0x74, 0x69, 0x6e, 0x67, 0x5f, 0x6d, 0x6c, 0x70, 0x5f, 0x31, 0x2f, 0x68,
    0x69, 0x64, 0x64, 0x65, 0x6e, 0x5f, 0x31, 0x5f, 0x31, 0x2f, 0x42, 0x69,
    0x61, 0x73, 0x41, 0x64, 0x64, 0x00, 0x00, 0x00, 0x02, 0x00, 0x00, 0x00,
    0x01, 0x00, 0x00, 0x00, 0x10, 0x00, 0x00, 0x00, 0x1e, 0xfd, 0xff, 0xff,
    0x00, 0x00, 0x00, 0x01, 0x14, 0x00, 0x00, 0x00, 0xe8, 0x00, 0x00, 0x00,
    0x05, 0x00, 0x00, 0x00, 0x00, 0x00, 0x00, 0x09, 0x04, 0x01, 0x00, 0x00,
    0x6c, 0xfc, 0xff, 0xff, 0x08, 0x00, 0x00, 0x00, 0x8c, 0x00, 0x00, 0x00,
    0x10, 0x00, 0x00, 0x00, 0x00, 0x00, 0x00, 0x00, 0x00, 0x00, 0x00, 0x00,
    0x00, 0x00, 0x00, 0x00, 0x00, 0x00, 0x00, 0x00, 0x00, 0x00, 0x00, 0x00,
    0x00, 0x00, 0x00, 0x00, 0x00, 0x00, 0x00, 0x00, 0x00, 0x00, 0x00, 0x00,
    0x00, 0x00, 0x00, 0x00, 0x00, 0x00, 0x00, 0x00, 0x00, 0x00, 0x00, 0x00,
    0x00, 0x00, 0x00, 0x00, 0x00, 0x00, 0x00, 0x00, 0x00, 0x00, 0x00, 0x00,
    0x00, 0x00, 0x00, 0x00, 0x00, 0x00, 0x00, 0x00, 0x00, 0x00, 0x00, 0x00,
    0x00, 0x00, 0x00, 0x00, 0x00, 0x00, 0x00, 0x00, 0x00, 0x00, 0x00, 0x00,
    0x00, 0x00, 0x00, 0x00, 0x00, 0x00, 0x00, 0x00, 0x00, 0x00, 0x00, 0x00,
    0x00, 0x00, 0x00, 0x00, 0x00, 0x00, 0x00, 0x00, 0x00, 0x00, 0x00, 0x00,
    0x00, 0x00, 0x00, 0x00, 0x00, 0x00, 0x00, 0x00, 0x00, 0x00, 0x00, 0x00,
    0x00, 0x00, 0x00, 0x00, 0x00, 0x00, 0x00, 0x00, 0x00, 0x00, 0x00, 0x00,
    0x00, 0x00, 0x00, 0x00, 0x10, 0x00, 0x00, 0x00, 0xbe, 0x2c, 0x2c, 0x3c,
    0xec, 0xd6, 0xea, 0x3b, 0xf1, 0x34, 0x0a, 0x3c, 0xbf, 0xfe, 0xc7, 0x3b,
    0x61, 0x28, 0x99, 0x3b, 0x78, 0x3d, 0x71, 0x3b, 0x02, 0xea, 0xba, 0x3b,
    0x2b, 0x59, 0x22, 0x3c, 0x4e, 0xda, 0x12, 0x3c, 0x49, 0x1c, 0x47, 0x3c,
    0x48, 0x9a, 0xbf, 0x3b, 0x50, 0x76, 0x64, 0x3b, 0x11, 0xa4, 0xf0, 0x3b,
    0xe3, 0xbf, 0xa8, 0x3b, 0x3a, 0x1e, 0x18, 0x3c, 0xaa, 0xfc, 0x69, 0x3b,
    0x20, 0x00, 0x00, 0x00, 0x6c, 0x69, 0x67, 0x68, 0x74, 0x69, 0x6e, 0x67,
    0x5f, 0x6d, 0x6c, 0x70, 0x5f, 0x31, 0x2f, 0x68, 0x69, 0x64, 0x64, 0x65,
    0x6e, 0x5f, 0x31, 0x5f, 0x31, 0x2f, 0x4d, 0x61, 0x74, 0x4d, 0x75, 0x6c,
    0x00, 0x00, 0x00, 0x00, 0x02, 0x00, 0x00, 0x00, 0x10, 0x00, 0x00, 0x00,
    0x07, 0x00, 0x00, 0x00, 0x46, 0xfe, 0xff, 0xff, 0x00, 0x00, 0x00, 0x01,
    0x14, 0x00, 0x00, 0x00, 0xe4, 0x00, 0x00, 0x00, 0x04, 0x00, 0x00, 0x00,
    0x00, 0x00, 0x00, 0x02, 0x20, 0x01, 0x00, 0x00, 0x94, 0xfd, 0xff, 0xff,
    0x08, 0x00, 0x00, 0x00, 0x88, 0x00, 0x00, 0x00, 0x10, 0x00, 0x00, 0x00,
    0x00, 0x00, 0x00, 0x00, 0x00, 0x00, 0x00, 0x00, 0x00, 0x00, 0x00, 0x00,
    0x00, 0x00, 0x00, 0x00, 0x00, 0x00, 0x00, 0x00, 0x00, 0x00, 0x00, 0x00,
    0x00, 0x00, 0x00, 0x00, 0x00, 0x00, 0x00, 0x00, 0x00, 0x00, 0x00, 0x00,
    0x00, 0x00, 0x00, 0x00, 0x00, 0x00, 0x00, 0x00, 0x00, 0x00, 0x00, 0x00,
    0x00, 0x00, 0x00, 0x00, 0x00, 0x00, 0x00, 0x00, 0x00, 0x00, 0x00, 0x00,
    0x00, 0x00, 0x00, 0x00, 0x00, 0x00, 0x00, 0x00, 0x00, 0x00, 0x00, 0x00,
    0x00, 0x00, 0x00, 0x00, 0x00, 0x00, 0x00, 0x00, 0x00, 0x00, 0x00, 0x00,
    0x00, 0x00, 0x00, 0x00, 0x00, 0x00, 0x00, 0x00, 0x00, 0x00, 0x00, 0x00,
    0x00, 0x00, 0x00, 0x00, 0x00, 0x00, 0x00, 0x00, 0x00, 0x00, 0x00, 0x00,
    0x00, 0x00, 0x00, 0x00, 0x00, 0x00, 0x00, 0x00, 0x00, 0x00, 0x00, 0x00,
    0x00, 0x00, 0x00, 0x00, 0x00, 0x00, 0x00, 0x00, 0x10, 0x00, 0x00, 0x00,
    0x90, 0xd9, 0xac, 0x38, 0xa5, 0xc2, 0x6b, 0x38, 0xab, 0xbf, 0x8a, 0x38,
    0x7e, 0xc7, 0x48, 0x38, 0x1d, 0xc2, 0x19, 0x38, 0x9d, 0x2f, 0xf2, 0x37,
    0xa0, 0xa5, 0x3b, 0x38, 0x20, 0xfc, 0xa2, 0x38, 0xb5, 0x6d, 0x93, 0x38,
    0x25, 0xe4, 0xc7, 0x38, 0x9a, 0x5a, 0x40, 0x38, 0xa2, 0x5b, 0xe5, 0x37,
    0x9c, 0x95, 0x71, 0x38, 0x45, 0x69, 0x29, 0x38, 0xea, 0xb6, 0x98, 0x38,
    0x88, 0xe7, 0xea, 0x37, 0x40, 0x00, 0x00, 0x00, 0x6c, 0x69, 0x67, 0x68,
    0x74, 0x69, 0x6e, 0x67, 0x5f, 0x6d, 0x6c, 0x70, 0x5f, 0x31, 0x2f, 0x68,
    0x69, 0x64, 0x64, 0x65, 0x6e, 0x5f, 0x31, 0x5f, 0x31, 0x2f, 0x52, 0x65,
    0x6c, 0x75, 0x3b, 0x6c, 0x69, 0x67, 0x68, 0x74, 0x69, 0x6e, 0x67, 0x5f,
    0x6d, 0x6c, 0x70, 0x5f, 0x31, 0x2f, 0x68, 0x69, 0x64, 0x64, 0x65, 0x6e,
    0x5f, 0x31, 0x5f, 0x31, 0x2f, 0x42, 0x69, 0x61, 0x73, 0x41, 0x64, 0x64,
    0x00, 0x00, 0x00, 0x00, 0x01, 0x00, 0x00, 0x00, 0x10, 0x00, 0x00, 0x00,
    0x86, 0xff, 0xff, 0xff, 0x00, 0x00, 0x00, 0x01, 0x14, 0x00, 0x00, 0x00,
    0x3c, 0x00, 0x00, 0x00, 0x03, 0x00, 0x00, 0x00, 0x00, 0x00, 0x00, 0x09,
    0x54, 0x00, 0x00, 0x00, 0xd4, 0xfe, 0xff, 0xff, 0x08, 0x00, 0x00, 0x00,
    0x18, 0x00, 0x00, 0x00, 0x02, 0x00, 0x00, 0x00, 0x00, 0x00, 0x00, 0x00,
    0x00, 0x00, 0x00, 0x00, 0x00, 0x00, 0x00, 0x00, 0x00, 0x00, 0x00, 0x00,
    0x02, 0x00, 0x00, 0x00, 0xe1, 0x83, 0x87, 0x3c, 0x32, 0xfe, 0x85, 0x3c,
    0x1e, 0x00, 0x00, 0x00, 0x6c, 0x69, 0x67, 0x68, 0x74, 0x69, 0x6e, 0x67,
    0x5f, 0x6d, 0x6c, 0x70, 0x5f, 0x31, 0x2f, 0x6f, 0x75, 0x74, 0x70, 0x75,
    0x74, 0x5f, 0x31, 0x2f, 0x4d, 0x61, 0x74, 0x4d, 0x75, 0x6c, 0x00, 0x00,
    0x02, 0x00, 0x00, 0x00, 0x02, 0x00, 0x00, 0x00, 0x10, 0x00, 0x00, 0x00,
    0x00, 0x00, 0x16, 0x00, 0x1c, 0x00, 0x18, 0x00, 0x17, 0x00, 0x10, 0x00,
    0x0c, 0x00, 0x08, 0x00, 0x00, 0x00, 0x00, 0x00, 0x00, 0x00, 0x07, 0x00,
    0x16, 0x00, 0x00, 0x00, 0x00, 0x00, 0x00, 0x01, 0x14, 0x00, 0x00, 0x00,
    0x3c, 0x00, 0x00, 0x00, 0x02, 0x00, 0x00, 0x00, 0x00, 0x00, 0x00, 0x02,
    0x54, 0x00, 0x00, 0x00, 0x64, 0xff, 0xff, 0xff, 0x08, 0x00, 0x00, 0x00,
    0x18, 0x00, 0x00, 0x00, 0x02, 0x00, 0x00, 0x00, 0x00, 0x00, 0x00, 0x00,
    0x00, 0x00, 0x00, 0x00, 0x00, 0x00, 0x00, 0x00, 0x00, 0x00, 0x00, 0x00,
    0x02, 0x00, 0x00, 0x00, 0xbd, 0xfe, 0x0f, 0x39, 0xac, 0x60, 0x0e, 0x39,
    0x1f, 0x00, 0x00, 0x00, 0x6c, 0x69, 0x67, 0x68, 0x74, 0x69, 0x6e, 0x67,
    0x5f, 0x6d, 0x6c, 0x70, 0x5f, 0x31, 0x2f, 0x6f, 0x75, 0x74, 0x70, 0x75,
    0x74, 0x5f, 0x31, 0x2f, 0x42, 0x69, 0x61, 0x73, 0x41, 0x64, 0x64, 0x00,
    0x01, 0x00, 0x00, 0x00, 0x02, 0x00, 0x00, 0x00, 0x00, 0x00, 0x16, 0x00,
    0x20, 0x00, 0x1c, 0x00, 0x1b, 0x00, 0x14, 0x00, 0x10, 0x00, 0x0c, 0x00,
    0x00, 0x00, 0x00, 0x00, 0x08, 0x00, 0x07, 0x00, 0x16, 0x00, 0x00, 0x00,
    0x00, 0x00, 0x00, 0x01, 0x18, 0x00, 0x00, 0x00, 0x2c, 0x00, 0x00, 0x00,
    0x48, 0x00, 0x00, 0x00, 0x01, 0x00, 0x00, 0x00, 0x00, 0x00, 0x00, 0x09,
    0x60, 0x00, 0x00, 0x00, 0x02, 0x00, 0x00, 0x00, 0xff, 0xff, 0xff, 0xff,
    0x07, 0x00, 0x00, 0x00, 0x0c, 0x00, 0x0c, 0x00, 0x00, 0x00, 0x00, 0x00,
    0x08, 0x00, 0x04, 0x00, 0x0c, 0x00, 0x00, 0x00, 0x08, 0x00, 0x00, 0x00,
    0x10, 0x00, 0x00, 0x00, 0x01, 0x00, 0x00, 0x00, 0xff, 0xff, 0xff, 0xff,
    0xff, 0xff, 0xff, 0xff, 0x01, 0x00, 0x00, 0x00, 0x7b, 0x80, 0x00, 0x3c,
    0x1e, 0x00, 0x00, 0x00, 0x73, 0x65, 0x72, 0x76, 0x69, 0x6e, 0x67, 0x5f,
    0x64, 0x65, 0x66, 0x61, 0x75, 0x6c, 0x74, 0x5f, 0x6b, 0x65, 0x72, 0x61,
    0x73, 0x5f, 0x74, 0x65, 0x6e, 0x73, 0x6f, 0x72, 0x3a, 0x30, 0x00, 0x00,
    0x02, 0x00, 0x00, 0x00, 0x01, 0x00, 0x00, 0x00, 0x07, 0x00, 0x00, 0x00,
    0x02, 0x00, 0x00, 0x00, 0x24, 0x00, 0x00, 0x00, 0x04, 0x00, 0x00, 0x00,
    0xf0, 0xff, 0xff, 0xff, 0x0e, 0x00, 0x00, 0x00, 0x02, 0x00, 0x00, 0x00,
    0x00, 0x00, 0x00, 0x0e, 0x0c, 0x00, 0x10, 0x00, 0x0f, 0x00, 0x00, 0x00,
    0x08, 0x00, 0x04, 0x00, 0x0c, 0x00, 0x00, 0x00, 0x09, 0x00, 0x00, 0x00,
    0x04, 0x00, 0x00, 0x00, 0x00, 0x00, 0x00, 0x09
};

#endif /* LIGHTING_MODEL_DATA_H_ */
```

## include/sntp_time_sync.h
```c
/*
 * SNTP Time Sync - 时间同步模块
 * Phase 2: WF-006 ~ WF-010
 *
 * 功能: SNTP初始化、时间同步、UTC+8时区转换、RTC更新
 */

#ifndef SNTP_TIME_SYNC_H
#define SNTP_TIME_SYNC_H

#include <stdint.h>
#include <stdbool.h>
#include <zephyr/posix/time.h>

/* 时区偏移: UTC+8 (中国标准时间) */
#define TIMEZONE_OFFSET_SECONDS  (8 * 3600)

/* NTP服务器 */
#define NTP_SERVER_1  "ntp.aliyun.com"
#define NTP_SERVER_2  "ntp.tencent.com"
#define NTP_SERVER_3  "pool.ntp.org"

/* 同步间隔 */
#define SNTP_SYNC_INTERVAL_S  3600   /* 每小时同步一次 */

/* 同步超时 */
#define SNTP_SYNC_TIMEOUT_S   30     /* 30秒超时 */

/* 本地时间结构体 */
typedef struct {
	int year;     /* 2026 */
	int month;    /* 1-12 */
	int day;      /* 1-31 */
	int hour;     /* 0-23 */
	int minute;   /* 0-59 */
	int second;   /* 0-59 */
	int weekday;  /* 0=Sunday, 1=Monday, ... */
} local_time_t;

/**
 * @brief 初始化SNTP客户端 (WF-006, WF-007)
 * @return 0=成功, 负值=失败
 */
int sntp_time_init(void);

/**
 * @brief 执行一次时间同步 (WF-008)
 * @return 0=成功, 负值=失败
 */
int sntp_time_sync(void);

/**
 * @brief 检查时间是否已同步
 * @return true=已同步
 */
bool sntp_time_is_synced(void);

/**
 * @brief 获取当前Unix时间戳 (秒)
 * @return 时间戳, 0=未同步
 */
int64_t sntp_time_get_timestamp(void);

/**
 * @brief UTC时间戳转本地时间 (WF-009)
 * @param timestamp Unix时间戳(秒)
 * @param local     输出本地时间结构体
 */
void sntp_time_utc_to_local(int64_t timestamp, local_time_t *local);

/**
 * @brief 获取当前本地时间 (便捷函数)
 * @param local 输出本地时间
 * @return 0=成功, 负值=未同步
 */
int sntp_time_get_local(local_time_t *local);

/**
 * @brief 获取当前本地小时数 (用于时段判断)
 * @return 小时数(0-23), 负值=未同步
 */
int sntp_time_get_hour(void);

/**
 * @brief 获取当前本地小时数（带小数部分）
 * @return 小时数 [0,24)，负值=未同步或失败
 */
float sntp_time_get_local_hour_f(void);

/**
 * @brief 更新系统RTC (WF-010)
 * @return 0=成功, 负值=失败
 */
int sntp_time_update_rtc(void);

/**
 * @brief SNTP周期同步线程 (WF-010)
 */
void sntp_time_thread_fn(void);

/**
 * @brief 启动SNTP周期同步线程（显式启动）
 * @return 0=成功
 */
int sntp_time_start(void);

/**
 * @brief 停止SNTP周期同步线程
 * @return 0=成功
 */
int sntp_time_stop(void);

#endif /* SNTP_TIME_SYNC_H */
```

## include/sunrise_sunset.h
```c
/*
 * Sunrise-Sunset API - 日出日落时间获取模块
 * Phase 2: WF-021 ~ WF-025
 *
 * 功能: sunrise-sunset.org API封装、JSON解析、时间转换、缓存、定时更新
 */

#ifndef SUNRISE_SUNSET_H
#define SUNRISE_SUNSET_H

#include <stdint.h>
#include <stdbool.h>

/* 太阳数据缓存结构体 (WF-024) */
typedef struct {
	float sunrise_hour;      /* 日出时间 (小时, 如 6.5 = 6:30) */
	float sunset_hour;       /* 日落时间 (小时, 如 18.75 = 18:45) */
	int day_of_year;         /* 数据对应的日期 (用于判断是否需要更新) */
	int64_t timestamp;       /* 获取时间 */
	bool valid;              /* 数据是否有效 */
} sun_cache_t;

/* 默认经纬度 (北京) */
#define SUN_DEFAULT_LATITUDE   39.9042
#define SUN_DEFAULT_LONGITUDE  116.4074

/* 缓存有效期: 24小时 */
#define SUN_CACHE_TTL_S  86400

/**
 * @brief 初始化日出日落模块 (WF-021)
 * @return 0=成功
 */
int sun_api_init(void);

/**
 * @brief 获取日出日落数据 (WF-021)
 * @param lat 纬度
 * @param lng 经度
 * @return 0=成功, 负值=失败
 */
int sun_fetch(double lat, double lng);

/**
 * @brief 解析JSON响应 (WF-022)
 * @param json_response API返回的JSON
 * @return 0=成功, 负值=失败
 */
int sun_parse_json(const char *json_response);

/**
 * @brief ISO8601时间转小时数 (WF-023)
 * @param iso_time ISO8601格式时间字符串 (如 "2026-04-24T06:30:00+00:00")
 * @return 小时数 (0-24), 如 6.5 表示 6:30
 */
float sun_iso_to_hour(const char *iso_time);

/**
 * @brief 获取日落临近度 (WF-026)
 * 返回当前时间距离日落的归一化值
 * @return 0.0=远离日落, 1.0=日落时刻, >1.0=日落后
 */
float sun_get_sunset_proximity(void);

/**
 * @brief 获取日出时间 (小时)
 * @return 日出小时数 (0-24), -1=无效
 */
float sun_get_sunrise_hour(void);

/**
 * @brief 获取日落时间 (小时)
 * @return 日落小时数 (0-24), -1=无效
 */
float sun_get_sunset_hour(void);

/**
 * @brief 获取太阳数据缓存 (WF-024)
 * @return 缓存指针 (只读)
 */
const sun_cache_t *sun_get_cache(void);

/**
 * @brief 检查缓存是否有效
 * @return true=有效
 */
bool sun_cache_is_valid(void);

/**
 * @brief 日出日落定时更新线程 (WF-025)
 */
void sun_update_thread_fn(void);

/**
 * @brief 启动日出日落更新线程（显式启动）
 * @return 0=成功
 */
int sun_api_start(void);

/**
 * @brief 停止日出日落更新线程
 * @return 0=成功
 */
int sun_api_stop(void);

#endif /* SUNRISE_SUNSET_H */
```

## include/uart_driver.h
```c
/*
 * UART Driver Header - 驱动板通信
 * Phase 1: HW-009 ~ HW-010
 *
 * 物理层: UART1 (TX=GPIO17, RX=GPIO18), 115200bps, 8N1, 无流控
 * 帧格式: [AA55][CMD][LEN][DATA...][校验和][0D0A]
 */

#ifndef UART_DRIVER_H
#define UART_DRIVER_H

#include <stdint.h>
#include <stddef.h>

/* 帧格式常量 */
#define FRAME_HEADER_HI    0xAA
#define FRAME_HEADER_LO    0x55
#define FRAME_FOOTER_HI    0x0D
#define FRAME_FOOTER_LO    0x0A
#define FRAME_HEADER_LEN   2
#define FRAME_FOOTER_LEN   2
#define FRAME_OVERHEAD     (FRAME_HEADER_LEN + 1 + 1 + 1 + FRAME_FOOTER_LEN) /* 头+CMD+LEN+校验+尾 = 7 */
#define FRAME_MAX_DATA     255
#define FRAME_MAX_TOTAL    (FRAME_OVERHEAD + FRAME_MAX_DATA)  /* = 262 */

/**
 * @brief 初始化UART1设备
 *        波特率115200, 8N1, 无硬件流控
 * @return 0=成功, 负值=失败
 */
int uart_driver_init(void);

/**
 * @brief 构建通信帧
 * @param cmd     命令字 (1字节)
 * @param data    数据缓冲区指针
 * @param data_len 数据长度 (0-255字节)
 * @param out_buf 输出缓冲区 (调用者分配, 需至少 FRAME_MAX_TOTAL 字节)
 * @return 帧总长度(字节), 负值=错误
 */
int frame_build(uint8_t cmd, const uint8_t *data, uint8_t data_len,
		uint8_t *out_buf);

/**
 * @brief 计算校验和 (从CMD到DATA的累加和低8位)
 * @param buf  数据缓冲区 (从CMD开始)
 * @param len  数据长度
 * @return 校验和(低8位)
 */
uint8_t calc_checksum(const uint8_t *buf, uint8_t len);

/**
 * @brief 通过UART发送帧数据
 * @param frame 帧缓冲区
 * @param len   帧长度
 * @return 0=成功, 负值=失败
 */
int uart_send_frame(const uint8_t *frame, uint8_t len);

/* 帧解析返回码 */
#define FRAME_PARSE_OK          0
#define FRAME_PARSE_ERR_HEADER -1
#define FRAME_PARSE_ERR_LENGTH -2
#define FRAME_PARSE_ERR_CSUM   -3
#define FRAME_PARSE_ERR_FOOTER -4

/**
 * @brief 解析接收到的帧数据
 * @param buf    输入缓冲区 (包含完整帧)
 * @param buf_len 缓冲区长度
 * @param cmd    输出: 解析出的命令字
 * @param data   输出: 解析出的数据 (调用者分配, 至少256字节)
 * @param data_len 输出: 解析出的数据长度
 * @return 0=成功, 负值=错误码
 */
int frame_parse(const uint8_t *buf, uint8_t buf_len,
		uint8_t *cmd, uint8_t *data, uint8_t *data_len);

/* 接收超时时间 */
#define UART_RECV_TIMEOUT_MS  500

/**
 * @brief 接收并解析响应帧 (带超时)
 * @param cmd      输出: 接收到的命令字
 * @param data     输出: 数据缓冲区
 * @param data_len 输出: 数据长度
 * @return 0=成功ACK, 负值=失败(NAK或超时)
 */
int uart_receive_response(uint8_t *cmd, uint8_t *data, uint8_t *data_len);

/* 重试参数 */
#define UART_MAX_RETRIES      3
#define UART_RETRY_DELAY_MS   100

/**
 * @brief 发送命令并等待响应 (带超时重试)
 * @param cmd      命令字
 * @param data     发送的数据
 * @param data_len 发送数据长度
 * @return 0=成功, 负值=失败
 */
int uart_send_with_retry(uint8_t cmd, const uint8_t *data, uint8_t data_len);

#endif /* UART_DRIVER_H */
```

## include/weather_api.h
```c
/*
 * Weather API - 天气数据获取模块
 * Phase 2: WF-016 ~ WF-020
 *
 * 功能: wttr.in API封装、天气解析、编码转换、缓存、定时更新
 */

#ifndef WEATHER_API_H
#define WEATHER_API_H

#include <stdint.h>
#include <stdbool.h>

/* 天气编码定义 (WF-018) */
typedef enum {
	WEATHER_SUNNY       = 0,    /* 晴天   → 编码 0.0 */
	WEATHER_PARTLY_CLOUDY = 1,  /* 少云   → 编码 0.25 */
	WEATHER_CLOUDY      = 2,    /* 多云   → 编码 0.5 */
	WEATHER_OVERCAST    = 3,    /* 阴天   → 编码 0.75 */
	WEATHER_RAIN_SNOW   = 4     /* 雨/雪  → 编码 1.0 */
} weather_type_t;

/* 天气编码值 (0.0 ~ 1.0) */
#define WEATHER_CODE_SUNNY          0.0f
#define WEATHER_CODE_PARTLY_CLOUDY  0.25f
#define WEATHER_CODE_CLOUDY         0.5f
#define WEATHER_CODE_OVERCAST       0.75f
#define WEATHER_CODE_RAIN_SNOW      1.0f

/* 天气缓存结构体 (WF-019) */
typedef struct {
	weather_type_t type;      /* 天气类型 */
	float code;               /* 0-1编码值 */
	int temperature;          /* 温度(℃) */
	int64_t timestamp;        /* 获取时间(Unix秒) */
	int64_t expires;          /* 过期时间(Unix秒) */
	bool valid;               /* 缓存是否有效 */
	char description[64];     /* 天气描述文本 */
} weather_cache_t;

/* 缓存有效期: 1小时 */
#define WEATHER_CACHE_TTL_S  3600

/* 默认城市 */
#define WEATHER_DEFAULT_CITY  "Beijing"

/**
 * @brief 初始化天气模块 (WF-016)
 * @return 0=成功
 */
int weather_api_init(void);

/**
 * @brief 获取天气数据 (WF-016)
 * @param city 城市名 (如 "Beijing"), NULL=使用默认
 * @return 0=成功, 负值=失败
 */
int weather_fetch(const char *city);

/**
 * @brief 解析天气响应文本 (WF-017)
 * @param response_text wttr.in原始响应
 * @return 0=成功, 负值=失败
 */
int weather_parse_response(const char *response_text);

/**
 * @brief 天气文本转数值编码 (WF-018)
 * @param description 天气描述文本
 * @return 编码值 (0.0 ~ 1.0)
 */
float weather_encode(const char *description);

/**
 * @brief 获取当前天气编码值 (0-1)
 * @return 编码值, -1.0=无效
 */
float weather_get_code(void);

/**
 * @brief 获取天气缓存 (WF-019)
 * @return 缓存指针 (只读), NULL=无效
 */
const weather_cache_t *weather_get_cache(void);

/**
 * @brief 检查缓存是否有效 (WF-019)
 * @return true=有效
 */
bool weather_cache_is_valid(void);

/**
 * @brief 天气定时更新线程 (WF-020)
 */
void weather_update_thread_fn(void);

#endif /* WEATHER_API_H */
```

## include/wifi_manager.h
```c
/*
 * WiFi Manager - WiFi连接管理
 * Phase 2: WF-002 ~ WF-005
 *
 * 功能: WiFi初始化、连接管理、自动重连、状态查询
 */

#ifndef WIFI_MANAGER_H
#define WIFI_MANAGER_H

#include <stdint.h>
#include <stdbool.h>
#include <zephyr/net/net_mgmt.h>
#include <zephyr/net/wifi_mgmt.h>

/* WiFi状态 */
typedef enum {
	WIFI_STATE_DISCONNECTED = 0,
	WIFI_STATE_CONNECTING,
	WIFI_STATE_CONNECTED,
	WIFI_STATE_GOT_IP,
	WIFI_STATE_ERROR
} wifi_state_t;

/* 重连参数 */
#define WIFI_RECONNECT_MIN_DELAY_MS   5000    /* 初始重连延迟 5s */
#define WIFI_RECONNECT_MAX_DELAY_MS   60000   /* 最大重连延迟 60s */
#define WIFI_RECONNECT_MAX_RETRIES    0       /* 0=无限重试 */

/* SSID/密码最大长度 */
#define WIFI_SSID_MAX_LEN    32
#define WIFI_PSK_MAX_LEN     64

/**
 * @brief 初始化WiFi管理器 (WF-002)
 * @return 0=成功, 负值=失败
 */
int wifi_manager_init(void);

/**
 * @brief 连接WiFi (WF-003)
 * @param ssid WiFi名称
 * @param psk  WiFi密码
 * @return 0=成功, 负值=失败
 */
int wifi_manager_connect(const char *ssid, const char *psk);

/**
 * @brief 断开WiFi连接
 * @return 0=成功, 负值=失败
 */
int wifi_manager_disconnect(void);

/**
 * @brief 获取当前WiFi状态 (WF-005)
 * @return wifi_state_t
 */
wifi_state_t wifi_manager_get_state(void);

/**
 * @brief 检查WiFi是否已连接并获取IP
 * @return true=已连接且获取到IP
 */
bool wifi_manager_is_connected(void);

/**
 * @brief 获取当前IP地址字符串 (WF-005)
 * @param buf  输出缓冲区
 * @param len  缓冲区长度
 * @return 0=成功, 负值=未连接
 */
int wifi_manager_get_ip(char *buf, size_t len);

/**
 * @brief 获取WiFi信号强度RSSI (WF-005)
 * @return RSSI值(dBm), 负值=失败
 */
int wifi_manager_get_rssi(void);

/**
 * @brief 注册WiFi状态变化回调 (WF-005)
 * @param cb 回调函数
 */
typedef void (*wifi_state_cb_t)(wifi_state_t new_state);
void wifi_manager_register_state_cb(wifi_state_cb_t cb);

/**
 * @brief WiFi管理器主循环 (WF-004: 重连逻辑)
 *        在独立线程中运行,处理断线重连
 */
void wifi_manager_thread_fn(void);

/**
 * @brief 启动WiFi管理线程（显式启动）
 * @return 0=成功
 */
int wifi_manager_start(void);

/**
 * @brief 停止WiFi管理线程
 * @return 0=成功
 */
int wifi_manager_stop(void);

#endif /* WIFI_MANAGER_H */
```
